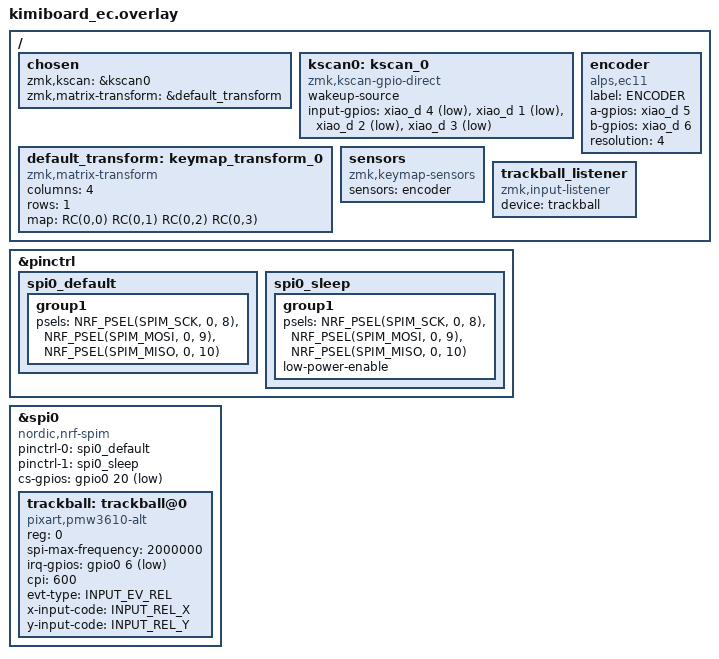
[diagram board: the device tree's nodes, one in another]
/*
 * KimiBoard EC - KimiBoard風トラックボールモジュール + ロータリーエンコーダー
 *
 * !!! 重要 !!!
 * 以下のピン番号 (&xiao_d N) はすべて「仮の値」です。
 * 実際の基板・配線に合わせて必ず書き換えてください。
 * XIAO nRF52840 (XIAO BLE) の D0〜D10 に対応する &xiao_d N 表記を使っています。
 *
 * 想定している配線 (要調整):
 *   D0 : (未使用 / 予備)
 *   D1 : キー1 (元のKimiBoardの1キー相当)
 *   D2 : キー2 (元のKimiBoardの2キー相当)
 *   D3 : キー3 (元のKimiBoardの3キー相当)
 *   D4 : タクトスイッチ (元のKimiBoardの0キー = Bluetooth切替用)
 *   D5 : エンコーダー A相 (新規追加)
 *   D6 : エンコーダー B相 (新規追加)
 *   D7 : PMW3610 CS (SPI チップセレクト)
 *   D8 : SPI SCK (XIAO BLEのデフォルトSPIピン)
 *   D9 : SPI MOSI
 *   D10: SPI MISO
 *   D0 (予備) : PMW3610 モーション割り込み(MOTION/INTピン)を別途割り当てる場合はここ等に変更
 */

#include <dt-bindings/zmk/matrix_transform.h>

/ {
    chosen {
        zmk,kscan = &kscan0;
        zmk,matrix-transform = &default_transform;
    };

    // ----------------------------------------------------
    // キースイッチ + タクトスイッチ (マトリクスなしの直結GPIO)
    // ----------------------------------------------------
    kscan0: kscan_0 {
        compatible = "zmk,kscan-gpio-direct";
        wakeup-source;
        input-gpios
            = <&xiao_d 4 GPIO_ACTIVE_LOW>  // index 0: タクトスイッチ (旧0キー / BT切替用)
            , <&xiao_d 1 GPIO_ACTIVE_LOW>  // index 1: キー1
            , <&xiao_d 2 GPIO_ACTIVE_LOW>  // index 2: キー2
            , <&xiao_d 3 GPIO_ACTIVE_LOW>  // index 3: キー3
            ;
    };

    // ----------------------------------------------------
    // 4キー、1行4列のマトリクス変換 (物理的な並びは自由に調整可)
    // ----------------------------------------------------
    default_transform: keymap_transform_0 {
        compatible = "zmk,matrix-transform";
        columns = <4>;
        rows = <1>;
        map = <
            RC(0,0) RC(0,1) RC(0,2) RC(0,3)
        >;
    };

    // ----------------------------------------------------
    // ロータリーエンコーダー (新規追加分)
    // ----------------------------------------------------
    encoder: encoder {
        compatible = "alps,ec11";
        label = "ENCODER";
        a-gpios = <&xiao_d 5 (GPIO_ACTIVE_HIGH | GPIO_PULL_UP)>;
        b-gpios = <&xiao_d 6 (GPIO_ACTIVE_HIGH | GPIO_PULL_UP)>;
        resolution = <4>;
        status = "okay";
    };

    sensors {
        compatible = "zmk,keymap-sensors";
        sensors = <&encoder>;
    };
};









#include "myball.dtsi"
#include <zephyr/dt-bindings/input/input-event-codes.h>

/*
 * トラックボール(PMW3610)を SPI で接続する設定。
 * badjeff/zmk-pmw3610-driver の作法に準拠。
 *
 * ★ 重要 ★
 * SCK / MOSI / MISO / CS(cs-gpios) / IRQ(irq-gpios) のピン番号は
 * すべて仮の値です。実際の配線に合わせて必ず書き換えてください。
 * (下記はnRF52840の生ピン番号 P0.xx の指定方法です)
 */

&pinctrl {
    spi0_default: spi0_default {
        group1 {
            psels = <NRF_PSEL(SPIM_SCK, 0, 8)>,
                    <NRF_PSEL(SPIM_MOSI, 0, 9)>,
                    <NRF_PSEL(SPIM_MISO, 0, 10)>;
        };
    };

    spi0_sleep: spi0_sleep {
        group1 {
            psels = <NRF_PSEL(SPIM_SCK, 0, 8)>,
                    <NRF_PSEL(SPIM_MOSI, 0, 9)>,
                    <NRF_PSEL(SPIM_MISO, 0, 10)>;
            low-power-enable;
        };
    };
};

&spi0 {
    status = "okay";
    compatible = "nordic,nrf-spim";
    pinctrl-0 = <&spi0_default>;
    pinctrl-1 = <&spi0_sleep>;
    pinctrl-names = "default", "sleep";
    cs-gpios = <&gpio0 20 GPIO_ACTIVE_LOW>;

    trackball: trackball@0 {
        status = "okay";
        compatible = "pixart,pmw3610-alt";
        reg = <0>;
        spi-max-frequency = <2000000>;
        irq-gpios = <&gpio0 6 (GPIO_ACTIVE_LOW | GPIO_PULL_UP)>;

        // CPI(感度)。数値を大きくするとカーソルが速く動く
        cpi = <600>;

        // 向きがおかしい場合は以下のコメントを外して調整
        // swap-xy;
        // invert-x;
        // invert-y;

        evt-type = <INPUT_EV_REL>;
        x-input-code = <INPUT_REL_X>;
        y-input-code = <INPUT_REL_Y>;
    };
};

/ {
    trackball_listener {
        compatible = "zmk,input-listener";
        device = <&trackball>;
    };
};
